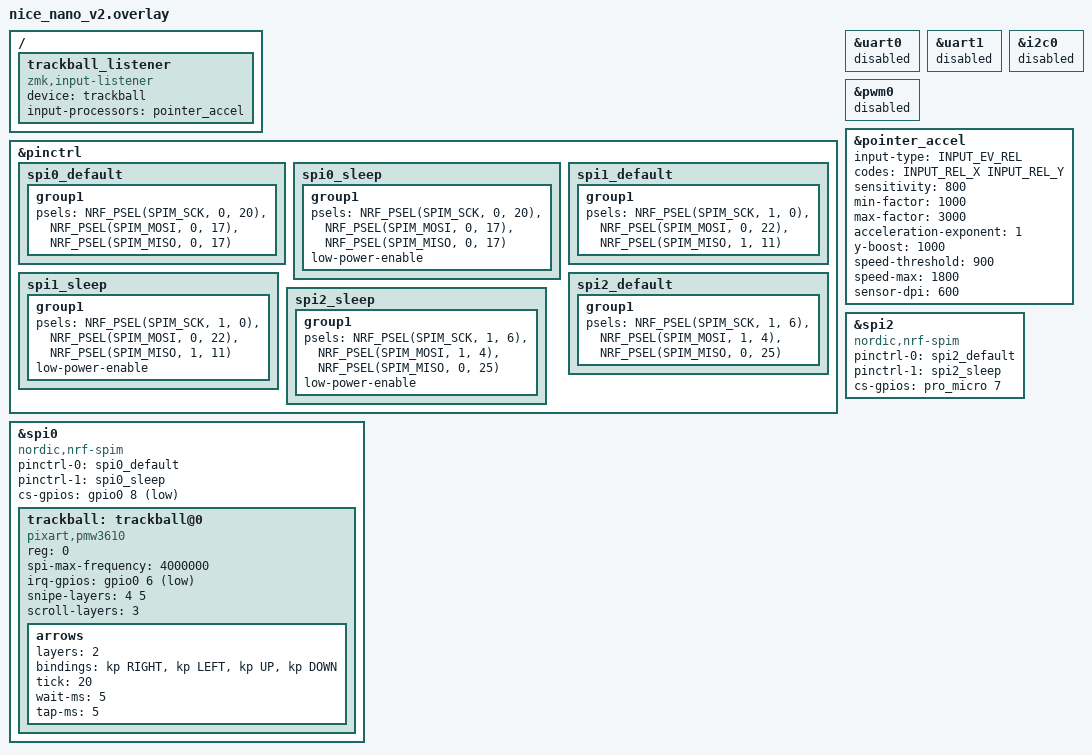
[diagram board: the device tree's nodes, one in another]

&pinctrl {
    spi0_default: spi0_default {
        group1 {
            psels = <NRF_PSEL(SPIM_SCK,  0, 20)>, // SCLK P0.20
                    <NRF_PSEL(SPIM_MOSI, 0, 17)>, // MOSI P0.17
                    <NRF_PSEL(SPIM_MISO, 0, 17)>; // MISO P0.06
        };
    };

    spi0_sleep: spi0_sleep {
        group1 {
            psels = <NRF_PSEL(SPIM_SCK,  0, 20)>, // SCLK P0.20
                    <NRF_PSEL(SPIM_MOSI, 0, 17)>, // MOSI/SDIO P0.17
                    <NRF_PSEL(SPIM_MISO, 0, 17)>; // MISO P0.06
            low-power-enable;
        };
    };

    spi1_default: spi1_default {
	    group1 {
		        psels = <NRF_PSEL(SPIM_SCK, 1, 0)>,
			            <NRF_PSEL(SPIM_MOSI, 0, 22)>,
                        <NRF_PSEL(SPIM_MISO, 1, 11)>;
	      };
    };

    spi1_sleep: spi1_sleep {
	    group1 {
		        psels = <NRF_PSEL(SPIM_SCK, 1, 0)>,
			            <NRF_PSEL(SPIM_MOSI, 0, 22)>,
                        <NRF_PSEL(SPIM_MISO, 1, 11)>;
                        low-power-enable;
	      };
    };

    spi2_default: spi2_default {
        group1 {
            psels = <NRF_PSEL(SPIM_SCK, 1, 6)>,
                    <NRF_PSEL(SPIM_MOSI, 1, 4)>,
                    <NRF_PSEL(SPIM_MISO, 0, 25)>;
          };
    };

    spi2_sleep: spi2_sleep {
        group1 {
            psels = <NRF_PSEL(SPIM_SCK, 1, 6)>,
                    <NRF_PSEL(SPIM_MOSI, 1, 4)>,
                    <NRF_PSEL(SPIM_MISO, 0, 25)>;
                    low-power-enable;
          };
    };

};

&uart0 {
	status = "disabled";
};

&uart1 {
	status = "disabled";
};

&i2c0 {
	status = "disabled";
};

&pwm0 {
	status = "disabled";
};


#include <zephyr/dt-bindings/input/input-event-codes.h>
#include <behaviors/input_gestures_accel.dtsi>
#include <behaviors.dtsi>
#include <dt-bindings/zmk/keys.h>

&pointer_accel { // this needs to be put BEFORE input-listener
    input-type = <INPUT_EV_REL>;
    codes = <INPUT_REL_X INPUT_REL_Y>;
    sensitivity = <800>;         // 0.8x base sensitivity
    min-factor = <600>;			  // 0.8x minimum for percision (MB 11/7 - 600 from 800)
    max-factor = <3000>;          // 3.0x maximum acceleration
    acceleration-exponent = <1>;  // Advanced exponential curve (1-5)
    y-boost = <1000>;             // 1.0x Y-axis boost for widescreen
    speed-threshold = <900>;      // Start acceleration at 900 counts/sec, just 1.5 inch/sec
    speed-max = <1800>;           // Max acceleration at 1800 counts/sec, just 3 inch/sec
    min-factor = <1000>;          // 1.0x minimum (no deceleration)
    sensor-dpi = <600>;
};

/* 
*/

nice_view_spi: &spi2 {
    compatible = "nordic,nrf-spim";
    pinctrl-0 = <&spi2_default>;
    pinctrl-1 = <&spi2_sleep>;
    pinctrl-names = "default", "sleep";
    cs-gpios = <&pro_micro 7 GPIO_ACTIVE_HIGH>;
};


&spi0 {
    status = "okay";
    compatible = "nordic,nrf-spim";
    pinctrl-0 = <&spi0_default>;
    pinctrl-1 = <&spi0_sleep>;
    pinctrl-names = "default", "sleep";
    cs-gpios = <&gpio0 8 GPIO_ACTIVE_LOW>;

    trackball: trackball@0 {
        status = "okay";
        compatible = "pixart,pmw3610";
        reg = <0>;
        spi-max-frequency = <4000000>;
        irq-gpios = <&gpio0 6 (GPIO_ACTIVE_LOW | GPIO_PULL_UP)>; // MISO/MOTION P0.06
        
        /* kumamuk options begin */ 
        /*   optional features   */
        // snipe-layers = <1>;
        // scroll-layers = <3>;
        // automouse-layer = <5>;
        snipe-layers = <4 5>;
        scroll-layers = <3>;

        /*   optional: ball action on specific layers  */
         arrows {
             layers = <2>;
             bindings = <&kp RIGHT>, <&kp LEFT>, <&kp UP>, <&kp DOWN>;
        
             /*   optional: ball action configuration  */
             tick = <20>;
              wait-ms = <5>;
              tap-ms = <5>;
         };
        /* kumamuk options end */ 

    };
};



/ {
  trackball_listener {
    compatible = "zmk,input-listener";
    status = "okay";
    device = <&trackball>;
    input-processors =
       <&pointer_accel>;
  };
};
